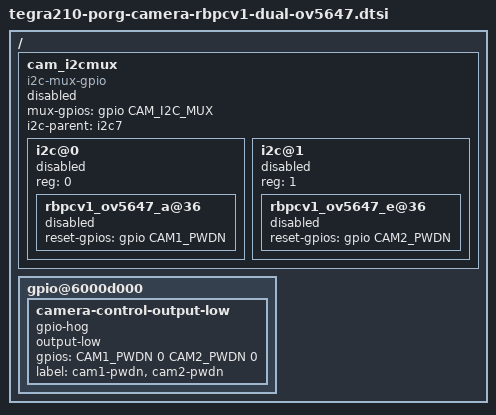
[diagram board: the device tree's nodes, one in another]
/*
 * tegra210-porg-camera-rbpcv1-dual-ov5647.dtsi
 *
 * Board wiring for two OV5647 modules on the Jetson Nano B01 carrier plus the
 * plugin-manager fix-ups that point Argus at the OV5647 nodes.
 *
 * Derived from NVIDIA's tegra210-porg-camera-rbpcv2-dual-imx219.dtsi (GPL-2.0).
 *
 * This program is free software; you can redistribute it and/or modify
 * it under the terms of the GNU General Public License as published by
 * the Free Software Foundation; either version 2 of the License, or
 * (at your option) any later version.
 */

#include "tegra210-camera-rbpcv1-dual-ov5647.dtsi"

#define CAM1_PWDN		TEGRA_GPIO(S, 7)
#define CAM2_PWDN		TEGRA_GPIO(T, 0)
#define CAM_I2C_MUX TEGRA_GPIO(I, 0) // NFC_EN GPIO

/ {
	cam_i2cmux {
		compatible = "i2c-mux-gpio";
		#address-cells = <1>;
		#size-cells = <0>;
		mux-gpios = <&gpio CAM_I2C_MUX GPIO_ACTIVE_HIGH>;
		i2c-parent = <&i2c7>;
		status = "disabled";
		i2c@0 {
			status = "disabled";
			reg = <0>;
			#address-cells = <1>;
			#size-cells = <0>;
			rbpcv1_ov5647_a@36 {
				status = "disabled";
				/* CAMx_PWDN gates the module's LDOs: high = powered */
				reset-gpios = <&gpio CAM1_PWDN GPIO_ACTIVE_HIGH>;
			};
		};
		i2c@1 {
			status = "disabled";
			reg = <1>;
			#address-cells = <1>;
			#size-cells = <0>;
			rbpcv1_ov5647_e@36 {
				status = "disabled";
				reset-gpios = <&gpio CAM2_PWDN GPIO_ACTIVE_HIGH>;
			};
		};
	};

	gpio@6000d000 {
		camera-control-output-low {
			gpio-hog;
			output-low;
			gpios = < CAM1_PWDN 0  CAM2_PWDN 0>;
			label = "cam1-pwdn", "cam2-pwdn";
		};
	};
};
